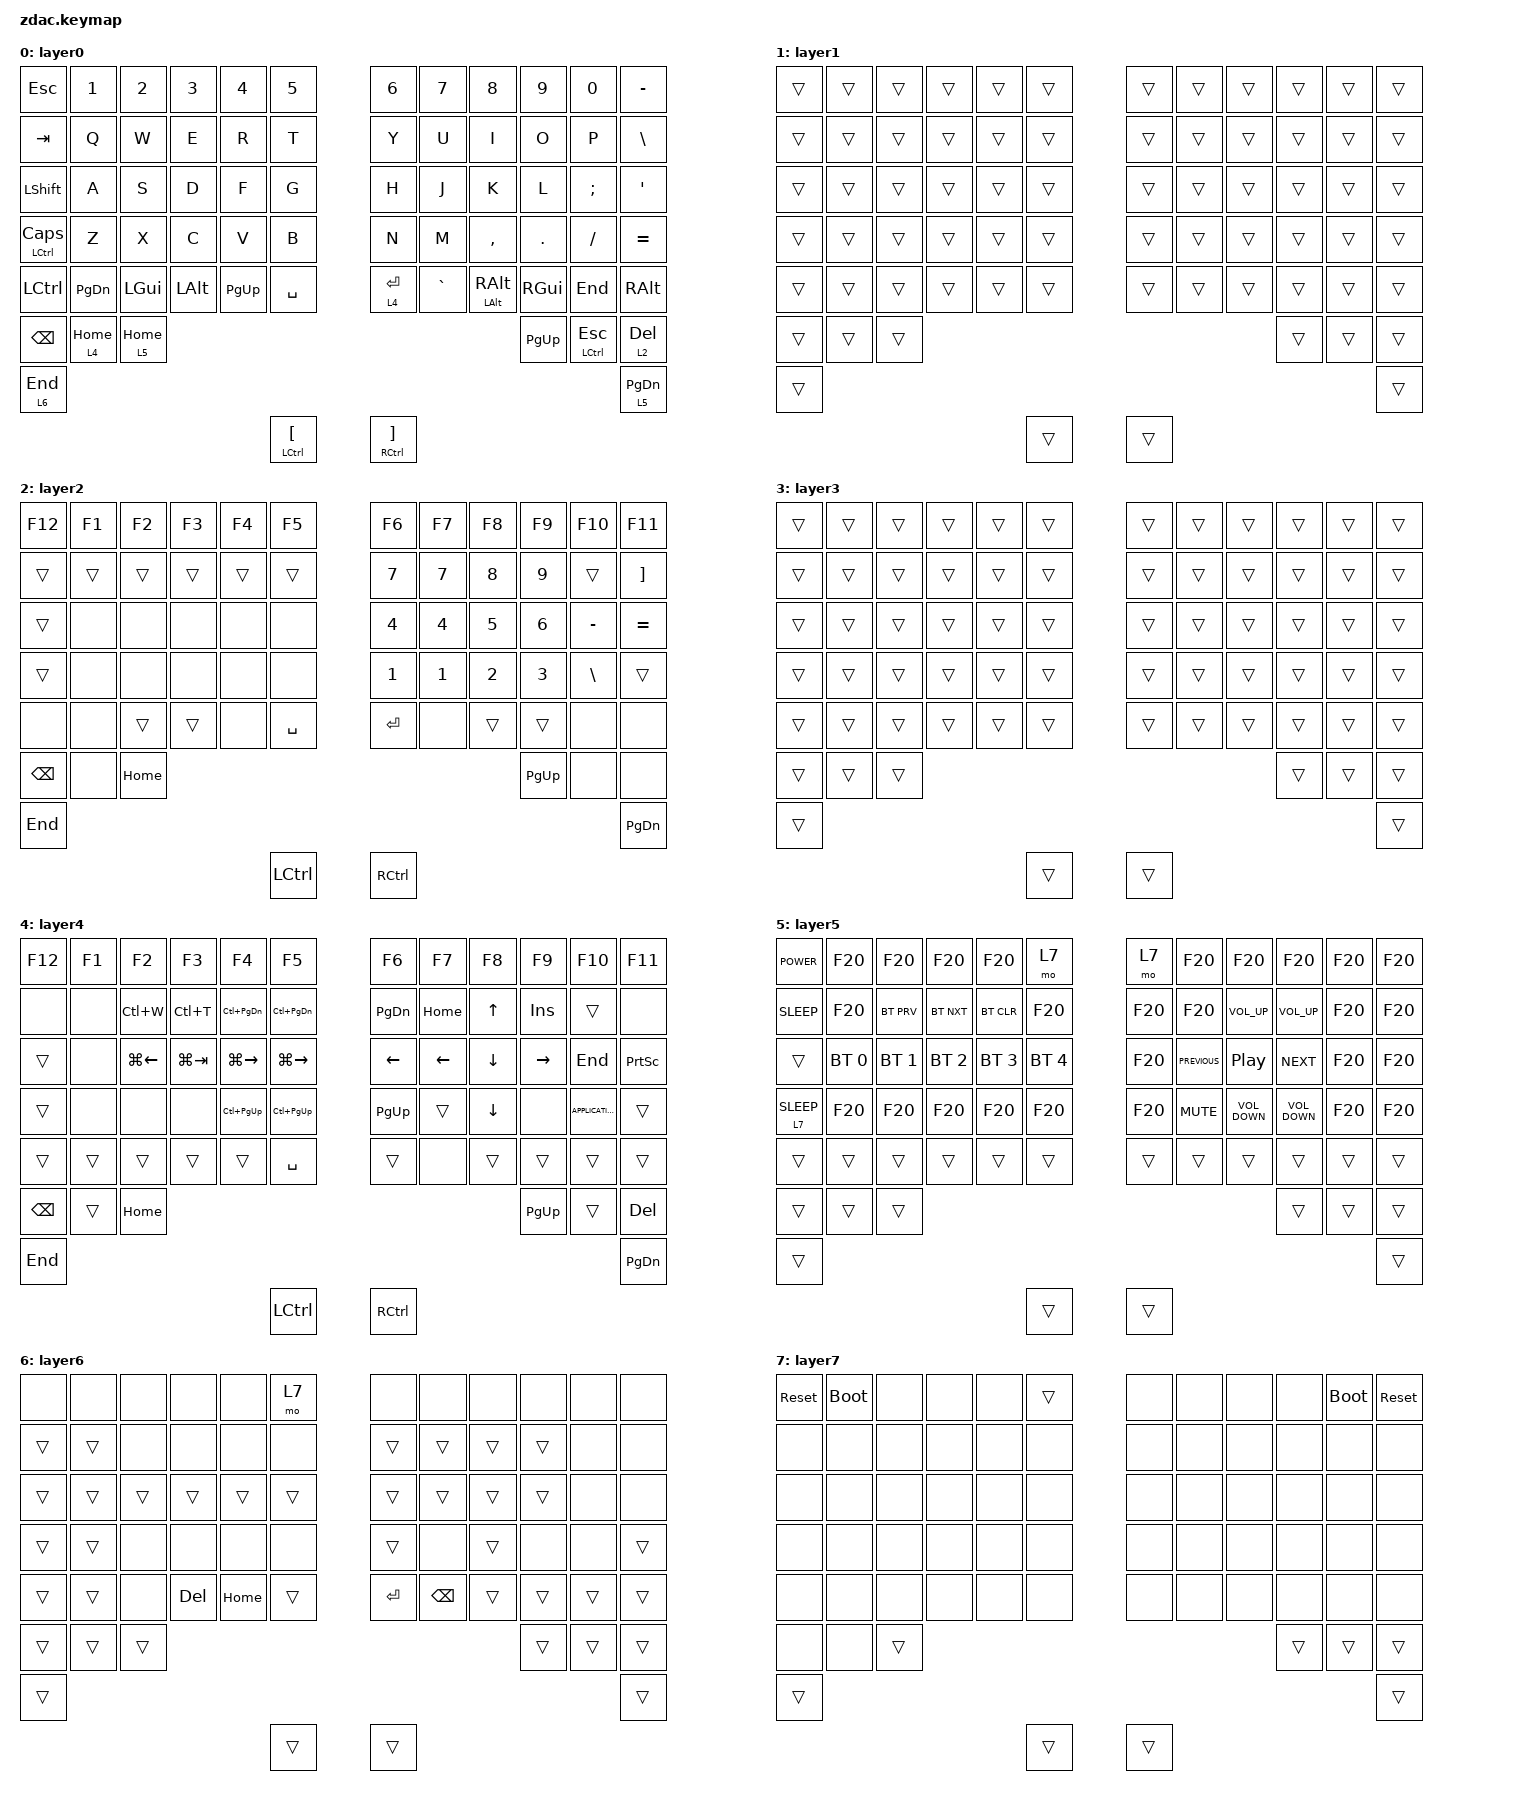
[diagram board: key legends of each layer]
/*
  * Copyright (c) 2020 The ZMK Contributors
  *
  * SPDX-License-Identifier: MIT
  */

#include <behaviors.dtsi>
#include <dt-bindings/zmk/bt.h>
#include <dt-bindings/zmk/keys.h>

/ {
    keymap {
        compatible = "zmk,keymap";

        layer0 {
            bindings = <
                    &kp ESC &kp N1 &kp N2 &kp N3 &kp N4 &kp N5                                  &kp N6 &kp N7 &kp N8 &kp N9 &kp N0 &kp MINUS 
                    &kp TAB &kp Q  &kp W  &kp E  &kp R &kp T                                    &kp Y  &kp U  &kp I  &kp O  &kp P  &kp BACKSLASH 
                    &kp LEFT_SHIFT &kp A &kp S &kp D &kp F &kp G                                &kp H  &kp J  &kp K  &kp L  &kp SEMICOLON &kp SINGLE_QUOTE 
               &mt LEFT_CONTROL CAPSLOCK &kp Z &kp X &kp C &kp V &kp B                          &kp N  &kp M  &kp COMMA &kp DOT &kp SLASH &kp EQUAL 
               &kp LEFT_CONTROL &kp PAGE_DOWN &kp LEFT_GUI &kp LEFT_ALT &kp PAGE_UP &kp SPACE   &lt 4 ENTER &kp GRAVE &mt LEFT_ALT RIGHT_ALT &kp RIGHT_GUI &kp END &kp RIGHT_ALT 
               &kp BACKSPACE &lt 4 HOME &lt 5 HOME                                              &kp PAGE_UP &mt LEFT_CONTROL ESCAPE &lt 2 DELETE 
               &lt 6 END                                                                        &lt 5 PAGE_DOWN 
               &mt LEFT_CONTROL LEFT_BRACKET                                                    &mt RIGHT_CONTROL RIGHT_BRACKET>;
        };


      layer1 {
          bindings = <
          &trans &trans &trans &trans &trans &trans &trans &trans &trans &trans &trans &trans &trans &trans &trans &trans &trans &trans &trans &trans &trans &trans &trans &trans &trans &trans &trans &trans &trans &trans &trans &trans &trans &trans &trans &trans &trans &trans &trans &trans &trans &trans &trans &trans &trans &trans &trans &trans &trans &trans &trans &trans &trans &trans &trans &trans &trans &trans &trans &trans &trans &trans &trans &trans &trans &trans &trans &trans &trans &trans
          >;
        };
        
        
        layer2 {
          bindings = <
          &kp F12 &kp F1 &kp F2 &kp F3 &kp F4 &kp F5 &kp F6 &kp F7 &kp F8 &kp F9 &kp F10 &kp F11 &trans &trans &trans &trans &trans &trans &kp N7 &kp N7 &kp N8 &kp N9 &trans &kp RIGHT_BRACKET &trans &none &none &none &none &none &kp N4 &kp N4 &kp N5 &kp N6 &kp MINUS &kp EQUAL &trans &none &none &none &none &none &kp N1 &kp N1 &kp N2 &kp N3 &kp BACKSLASH &trans &none &none &trans &trans &none &kp SPACE &kp ENTER &none &trans &trans &none &none &kp BACKSPACE &none &kp HOME &kp PAGE_UP &none &none &kp END &kp PAGE_DOWN &kp LEFT_CONTROL &kp RIGHT_CONTROL
          >;
        };
        
        layer3 {
          bindings = <
          &trans &trans &trans &trans &trans &trans &trans &trans &trans &trans &trans &trans &trans &trans &trans &trans &trans &trans &trans &trans &trans &trans &trans &trans &trans &trans &trans &trans &trans &trans &trans &trans &trans &trans &trans &trans &trans &trans &trans &trans &trans &trans &trans &trans &trans &trans &trans &trans &trans &trans &trans &trans &trans &trans &trans &trans &trans &trans &trans &trans &trans &trans &trans &trans &trans &trans &trans &trans &trans &trans
          >;
        };
        
        layer4 {
          bindings = <
          &kp F12 &kp F1 &kp F2 &kp F3 &kp F4 &kp F5                                          &kp F6 &kp F7 &kp F8 &kp F9 &kp F10 &kp F11 
          &none &none &kp LC(W) &kp LC(T) &kp LC(PAGE_DOWN) &kp LC(PAGE_DOWN)                 &kp PAGE_DOWN   &kp HOME &kp UP &kp INSERT &trans &none 
          &trans &none &kp LG(LEFT) &kp LG(TAB) &kp LG(RIGHT) &kp LG(RIGHT)                   &kp LEFT &kp LEFT &kp DOWN     &kp RIGHT &kp END &kp PRINTSCREEN 
          &trans &none &none &none &kp LC(PAGE_UP) &kp LC(PAGE_UP)                            &kp PAGE_UP &trans &kp DOWN &none &kp K_APPLICATION &trans 
          &trans &trans &trans &trans &trans &kp SPACE                                        &trans &none &trans &trans &trans &trans 
          &kp BACKSPACE &trans &kp HOME                                                       &kp PAGE_UP &trans &kp DELETE                         
          &kp END                                                                             &kp PAGE_DOWN 
          &kp LEFT_CONTROL                                                                    &kp RIGHT_CONTROL
          >; 
        };

        layer5 {
            bindings = <
                        &kp K_POWER  &kp F20  &kp F20  &kp F20  &kp F20  &mo 7                             &mo 7    &kp F20  &kp F20  &kp F20  &kp F20  &kp F20  
                        &kp K_SLEEP  &kp F20  &bt BT_PRV  &bt BT_NXT  &bt BT_CLR  &kp F20                  &kp F20  &kp F20  &kp C_VOLUME_UP  &kp C_VOLUME_UP  &kp F20  &kp F20  
                        &trans       &bt BT_SEL 0  &bt BT_SEL 1  &bt BT_SEL 2  &bt BT_SEL 3  &bt BT_SEL 4  &kp F20  &kp C_PREVIOUS  &kp C_PLAY_PAUSE  &kp C_NEXT  &kp F20  &kp F20  
                        &lt 7 K_SLEEP &kp F20  &kp F20  &kp F20  &kp F20  &kp F20                          &kp F20  &kp C_MUTE  &kp C_VOLUME_DOWN  &kp C_VOLUME_DOWN  &kp F20  &kp F20  
                        &trans  &trans  &trans  &trans  &trans  &trans                                     &trans &trans  &trans  &trans  &trans  &trans  
                        &trans  &trans  &trans                                                             &trans &trans &trans  
                        &trans                                                                             &trans                                                                    
                        &trans                                                                             &trans
            >;
        };

       layer6 {
          bindings = <
          &none &none &none &none &none &mo 7 &none &none &none &none &none &none &trans &trans &none &none &none &none &trans &trans &trans &trans &none &none &trans &trans &trans &trans &trans &trans &trans &trans &trans &trans &none &none &trans &trans &none &none &none &none &trans &none &trans &none &none &trans &trans &trans &none &kp DELETE &kp HOME &trans &kp ENTER &kp BACKSPACE &trans &trans &trans &trans &trans &trans &trans &trans &trans &trans &trans &trans &trans &trans
          >;
        };
        
        layer7 {
          bindings = <
          &sys_reset &bootloader &none &none &none &trans                                                &none &none &none &none &bootloader &sys_reset 
          &none &none &none &none &none &none                                                            &none &none &none &none &none &none 
          &none &none &none &none &none &none                                                            &none &none &none &none &none &none 
          &none &none &none &none &none &none                                                            &none &none &none &none &none &none 
          &none &none &none &none &none &none                                                            &none &none &none &none &none &none 
          &none &none &trans                                                                             &trans &trans &trans 
          &trans                                                                                         &trans 
          &trans                                                                                         &trans
          >;
        };
    };
  }; 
